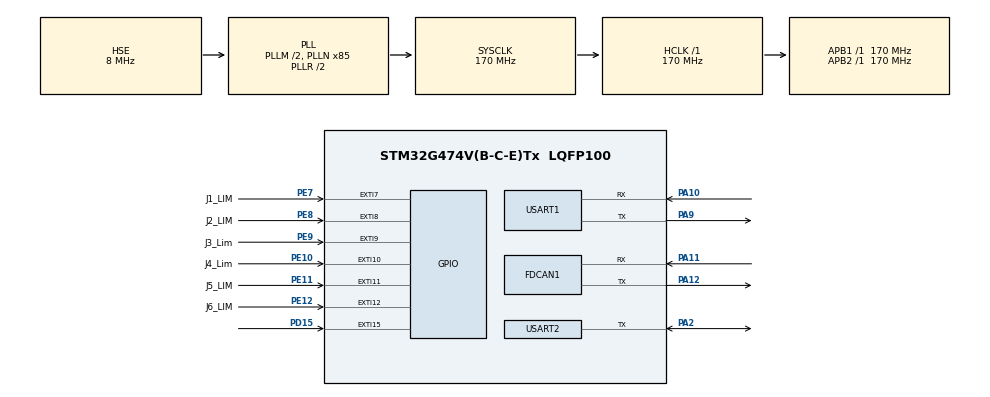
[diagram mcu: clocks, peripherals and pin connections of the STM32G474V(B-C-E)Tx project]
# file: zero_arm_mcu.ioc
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Dma.Request0=USART1_RX
Dma.Request1=USART1_TX
Dma.USART1_RX.0.Direction=DMA_PERIPH_TO_MEMORY
Dma.USART1_RX.0.EventEnable=DISABLE
Dma.USART1_RX.0.Instance=DMA1_Channel1
Dma.USART1_RX.0.MemDataAlignment=DMA_MDATAALIGN_BYTE
Dma.USART1_RX.0.MemInc=DMA_MINC_ENABLE
Dma.USART1_RX.0.Mode=DMA_CIRCULAR
Dma.USART1_RX.0.PeriphDataAlignment=DMA_PDATAALIGN_BYTE
Dma.USART1_RX.0.PeriphInc=DMA_PINC_DISABLE
Dma.USART1_RX.0.Polarity=HAL_DMAMUX_REQ_GEN_RISING
Dma.USART1_RX.0.Priority=DMA_PRIORITY_HIGH
Dma.USART1_RX.0.RequestNumber=1
Dma.USART1_RX.0.SignalID=NONE
Dma.USART1_RX.0.SyncEnable=DISABLE
Dma.USART1_RX.0.SyncPolarity=HAL_DMAMUX_SYNC_NO_EVENT
Dma.USART1_RX.0.SyncRequestNumber=1
Dma.USART1_RX.0.SyncSignalID=NONE
Dma.USART1_TX.1.Direction=DMA_MEMORY_TO_PERIPH
Dma.USART1_TX.1.EventEnable=DISABLE
Dma.USART1_TX.1.Instance=DMA1_Channel2
Dma.USART1_TX.1.MemDataAlignment=DMA_MDATAALIGN_BYTE
Dma.USART1_TX.1.MemInc=DMA_MINC_ENABLE
Dma.USART1_TX.1.Mode=DMA_NORMAL
Dma.USART1_TX.1.PeriphDataAlignment=DMA_PDATAALIGN_BYTE
Dma.USART1_TX.1.PeriphInc=DMA_PINC_DISABLE
Dma.USART1_TX.1.Polarity=HAL_DMAMUX_REQ_GEN_RISING
Dma.USART1_TX.1.Priority=DMA_PRIORITY_MEDIUM
Dma.USART1_TX.1.RequestNumber=1
Dma.USART1_TX.1.SignalID=NONE
Dma.USART1_TX.1.SyncEnable=DISABLE
Dma.USART1_TX.1.SyncPolarity=HAL_DMAMUX_SYNC_NO_EVENT
Dma.USART1_TX.1.SyncRequestNumber=1
Dma.USART1_TX.1.SyncSignalID=NONE
FDCAN1.AutoRetransmission=ENABLE
FDCAN1.CalculateBaudRateNominal=500000
FDCAN1.CalculateTimeBitNominal=2000
FDCAN1.CalculateTimeQuantumNominal=100.0
FDCAN1.ExtFiltersNbr=1
FDCAN1.NominalPrescaler=17
FDCAN1.NominalTimeSeg1=15
FDCAN1.NominalTimeSeg2=4
FREERTOS.Tasks01=InitTask,24,128,StartInitTask,Default,NULL,Dynamic,NULL,NULL
FREERTOS.configTOTAL_HEAP_SIZE=16000
Mcu.Family=STM32G4
Mcu.Name=STM32G474V(B-C-E)Tx
Mcu.Package=LQFP100
NVIC.DMA1_Channel1_IRQn=true\:7\:0\:true\:false\:true\:true\:false\:true\:true
NVIC.DMA1_Channel2_IRQn=true\:7\:0\:true\:false\:true\:true\:false\:true\:true
NVIC.EXTI15_10_IRQn=true\:6\:0\:true\:false\:true\:true\:true\:true\:true
NVIC.EXTI9_5_IRQn=true\:6\:0\:true\:false\:true\:true\:true\:true\:true
NVIC.FDCAN1_IT0_IRQn=true\:6\:0\:true\:false\:true\:true\:true\:true\:true
NVIC.PriorityGroup=NVIC_PRIORITYGROUP_4
NVIC.TIM6_DAC_IRQn=true\:15\:0\:false\:false\:true\:false\:false\:true\:true
NVIC.TimeBase=TIM6_DAC_IRQn
NVIC.TimeBaseIP=TIM6
NVIC.USART1_IRQn=true\:7\:0\:true\:false\:true\:true\:false\:true\:true
PA10.Mode=Asynchronous
PA10.Signal=USART1_RX
PA11.Mode=FDCAN_Activate
PA11.Signal=FDCAN1_RX
PA12.Mode=FDCAN_Activate
PA12.Signal=FDCAN1_TX
PA13.Mode=Serial_Wire
PA13.Signal=SYS_JTMS-SWDIO
PA14.Mode=Serial_Wire
PA14.Signal=SYS_JTCK-SWCLK
PA2.Mode=Half_duplex(single_wire_mode)
PA2.Signal=USART2_TX
PA9.Mode=Asynchronous
PA9.Signal=USART1_TX
PD15.GPIO_ModeDefaultEXTI=GPIO_MODE_IT_FALLING
PD15.GPIO_PuPd=GPIO_PULLUP
PD15.Signal=GPXTI15
PE10.GPIO_Label=J4_Lim
PE10.GPIO_PuPd=GPIO_PULLUP
PE10.Signal=GPXTI10
PE11.GPIO_Label=J5_LIM
PE11.GPIO_PuPd=GPIO_PULLUP
PE11.Signal=GPXTI11
PE12.GPIO_Label=J6_LIM
PE12.GPIO_PuPd=GPIO_PULLUP
PE12.Signal=GPXTI12
PE7.GPIO_Label=J1_LIM
PE7.GPIO_PuPd=GPIO_PULLUP
PE7.Signal=GPXTI7
PE8.GPIO_Label=J2_LIM
PE8.GPIO_PuPd=GPIO_PULLUP
PE8.Signal=GPXTI8
PE9.GPIO_Label=J3_Lim
PE9.GPIO_PuPd=GPIO_PULLUP
PE9.Signal=GPXTI9
PF0-OSC_IN.Mode=HSE-External-Oscillator
PF0-OSC_IN.Signal=RCC_OSC_IN
PF1-OSC_OUT.Mode=HSE-External-Oscillator
PF1-OSC_OUT.Signal=RCC_OSC_OUT
ProjectManager.HeapSize=0x200
ProjectManager.StackSize=0x400
ProjectManager.TargetToolchain=CMake
RCC.ADC12Freq_Value=170000000
RCC.ADC345Freq_Value=170000000
RCC.AHBFreq_Value=170000000
RCC.APB1Freq_Value=170000000
RCC.APB1TimFreq_Value=170000000
RCC.APB2Freq_Value=170000000
RCC.APB2TimFreq_Value=170000000
RCC.CortexFreq_Value=170000000
RCC.EXTERNAL_CLOCK_VALUE=12288000
RCC.HCLKFreq_Value=170000000
RCC.HSE_VALUE=8000000
RCC.HSI48_VALUE=48000000
RCC.HSI_VALUE=16000000
RCC.LSE_VALUE=32768
RCC.PLLM=RCC_PLLM_DIV2
RCC.PLLN=85
RCC.PLLSourceVirtual=RCC_PLLSOURCE_HSE
RCC.SYSCLKFreq_VALUE=170000000
RCC.SYSCLKSource=RCC_SYSCLKSOURCE_PLLCLK
RCC.USBFreq_Value=170000000
RCC.VCOOutputFreq_Value=340000000
USART1.VirtualMode-Asynchronous=VM_ASYNC
USART2.BaudRate=1000000
USART2.VirtualMode-Half_duplex(single_wire_mode)=VM_ASYNC
VP_FREERTOS_VS_CMSIS_V2.Mode=CMSIS_V2
VP_SYS_VS_DBSignals.Mode=DisableDeadBatterySignals
VP_SYS_VS_tim6.Mode=TIM6
board=custom

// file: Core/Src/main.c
/* USER CODE BEGIN Header */
/**
  ******************************************************************************
  * @file           : main.c
  * @brief          : Main program body
  ******************************************************************************
  * @attention
  *
  * Copyright (c) 2026 STMicroelectronics.
  * All rights reserved.
  *
  * This software is licensed under terms that can be found in the LICENSE file
  * in the root directory of this software component.
  * If no LICENSE file comes with this software, it is provided AS-IS.
  *
  ******************************************************************************
  */
/* USER CODE END Header */
#include "main.h"
#include "cmsis_os.h"
#include "dma.h"
#include "fdcan.h"
#include "usart.h"
#include "gpio.h"

void SystemClock_Config(void);
void MX_FREERTOS_Init(void);

int main(void)
{

  /* MCU Configuration--------------------------------------------------------*/

  /* Reset of all peripherals, Initializes the Flash interface and the Systick. */
  HAL_Init();

  /* Configure the system clock */
  SystemClock_Config();

  /* Initialize all configured peripherals */
  MX_GPIO_Init();
  MX_DMA_Init();
  MX_FDCAN1_Init();
  MX_USART1_UART_Init();
  MX_USART2_UART_Init();

  /* Init scheduler */
  osKernelInitialize();  /* Call init function for freertos objects (in cmsis_os2.c) */
  MX_FREERTOS_Init();

  /* Start scheduler */
  osKernelStart();

  /* We should never get here as control is now taken by the scheduler */

  /* Infinite loop */
  while (1)
  {

  }
}

void SystemClock_Config(void)
{
  RCC_OscInitTypeDef RCC_OscInitStruct = {0};
  RCC_ClkInitTypeDef RCC_ClkInitStruct = {0};

  /** Configure the main internal regulator output voltage
  */
  HAL_PWREx_ControlVoltageScaling(PWR_REGULATOR_VOLTAGE_SCALE1_BOOST);

  /** Initializes the RCC Oscillators according to the specified parameters
  * in the RCC_OscInitTypeDef structure.
  */
  RCC_OscInitStruct.OscillatorType = RCC_OSCILLATORTYPE_HSE;
  RCC_OscInitStruct.HSEState = RCC_HSE_ON;
  RCC_OscInitStruct.PLL.PLLState = RCC_PLL_ON;
  RCC_OscInitStruct.PLL.PLLSource = RCC_PLLSOURCE_HSE;
  RCC_OscInitStruct.PLL.PLLM = RCC_PLLM_DIV2;
  RCC_OscInitStruct.PLL.PLLN = 85;
  RCC_OscInitStruct.PLL.PLLP = RCC_PLLP_DIV2;
  RCC_OscInitStruct.PLL.PLLQ = RCC_PLLQ_DIV2;
  RCC_OscInitStruct.PLL.PLLR = RCC_PLLR_DIV2;
  if (HAL_RCC_OscConfig(&RCC_OscInitStruct) != HAL_OK)
  {
    Error_Handler();
  }

  /** Initializes the CPU, AHB and APB buses clocks
  */
  RCC_ClkInitStruct.ClockType = RCC_CLOCKTYPE_HCLK|RCC_CLOCKTYPE_SYSCLK
                              |RCC_CLOCKTYPE_PCLK1|RCC_CLOCKTYPE_PCLK2;
  RCC_ClkInitStruct.SYSCLKSource = RCC_SYSCLKSOURCE_PLLCLK;
  RCC_ClkInitStruct.AHBCLKDivider = RCC_SYSCLK_DIV1;
  RCC_ClkInitStruct.APB1CLKDivider = RCC_HCLK_DIV1;
  RCC_ClkInitStruct.APB2CLKDivider = RCC_HCLK_DIV1;

  if (HAL_RCC_ClockConfig(&RCC_ClkInitStruct, FLASH_LATENCY_4) != HAL_OK)
  {
    Error_Handler();
  }
}

void HAL_TIM_PeriodElapsedCallback(TIM_HandleTypeDef *htim)
{
  if (htim->Instance == TIM6)
  {
    HAL_IncTick();
  }
}

void Error_Handler(void)
{
  __disable_irq();
  while (1)
  {
  }
}

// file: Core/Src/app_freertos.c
/* USER CODE BEGIN Header */
/**
  ******************************************************************************
  * File Name          : app_freertos.c
  * Description        : Code for freertos applications
  ******************************************************************************
  * @attention
  *
  * Copyright (c) 2026 STMicroelectronics.
  * All rights reserved.
  *
  * This software is licensed under terms that can be found in the LICENSE file
  * in the root directory of this software component.
  * If no LICENSE file comes with this software, it is provided AS-IS.
  *
  ******************************************************************************
  */
/* USER CODE END Header */

#include "FreeRTOS.h"
#include "task.h"
#include "main.h"
#include "cmsis_os.h"

/* USER CODE BEGIN Includes */
#include "app.h"
/* USER CODE END Includes */

/* Definitions for InitTask */
osThreadId_t InitTaskHandle;
const osThreadAttr_t InitTask_attributes = {
  .name = "InitTask",
  .priority = (osPriority_t) osPriorityNormal,
  .stack_size = 128 * 4
};

void StartInitTask(void *argument);

void MX_FREERTOS_Init(void); /* (MISRA C 2004 rule 8.1) */

void MX_FREERTOS_Init(void) {

  /* Create the thread(s) */
  /* creation of InitTask */
  InitTaskHandle = osThreadNew(StartInitTask, NULL, &InitTask_attributes);

}

void StartInitTask(void *argument)
{
  /* USER CODE BEGIN StartInitTask */
  (void)argument;

  if (!app_start()) {
    Error_Handler();
  }

  osThreadExit();
  /* USER CODE END StartInitTask */
}
